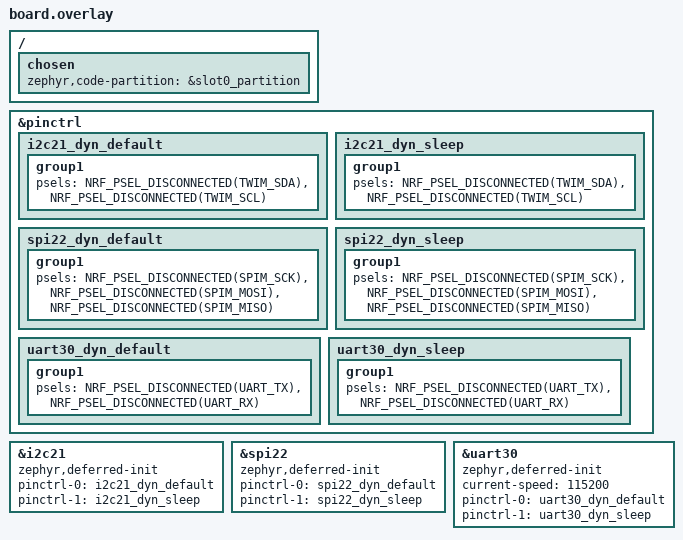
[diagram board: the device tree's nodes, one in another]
// nRF54L15 DK doesn't have USB, so no app.overlay for CDC ACM.

// Enable every free serial peripheral instance so CircuitPython can mux it to
// arbitrary pins at runtime. Each instance is enabled in one mode because the
// i2c/spi/uart nodes of an instance are the same peripheral (enforced by
// zephyr/soc/nordic/validate_enabled_instances.c). All signals are
// disconnected and the devices are marked zephyr,deferred-init so nothing is
// claimed at boot; iobroker initializes and routes a device when a busio
// object is constructed and de-initializes it on release.
//
// Instance 20 is left alone: uart20 is the console (main UART) and i2c20/spi20
// share that same peripheral, so they must not be enabled. Instance 00 is
// owned by spi00 and the MX25R64 SPI flash (no TWI00 on this SoC).

&pinctrl {
	i2c21_dyn_default: i2c21_dyn_default {
		group1 {
			psels = <NRF_PSEL_DISCONNECTED(TWIM_SDA)>,
				<NRF_PSEL_DISCONNECTED(TWIM_SCL)>;
		};
	};

	i2c21_dyn_sleep: i2c21_dyn_sleep {
		group1 {
			psels = <NRF_PSEL_DISCONNECTED(TWIM_SDA)>,
				<NRF_PSEL_DISCONNECTED(TWIM_SCL)>;
		};
	};

	spi22_dyn_default: spi22_dyn_default {
		group1 {
			psels = <NRF_PSEL_DISCONNECTED(SPIM_SCK)>,
				<NRF_PSEL_DISCONNECTED(SPIM_MOSI)>,
				<NRF_PSEL_DISCONNECTED(SPIM_MISO)>;
		};
	};

	spi22_dyn_sleep: spi22_dyn_sleep {
		group1 {
			psels = <NRF_PSEL_DISCONNECTED(SPIM_SCK)>,
				<NRF_PSEL_DISCONNECTED(SPIM_MOSI)>,
				<NRF_PSEL_DISCONNECTED(SPIM_MISO)>;
		};
	};

	uart30_dyn_default: uart30_dyn_default {
		group1 {
			psels = <NRF_PSEL_DISCONNECTED(UART_TX)>,
				<NRF_PSEL_DISCONNECTED(UART_RX)>;
		};
	};

	uart30_dyn_sleep: uart30_dyn_sleep {
		group1 {
			psels = <NRF_PSEL_DISCONNECTED(UART_TX)>,
				<NRF_PSEL_DISCONNECTED(UART_RX)>;
		};
	};
};

&i2c21 {
	status = "okay";
	zephyr,deferred-init;
	pinctrl-0 = <&i2c21_dyn_default>;
	pinctrl-1 = <&i2c21_dyn_sleep>;
	pinctrl-names = "default", "sleep";
};

&spi22 {
	status = "okay";
	zephyr,deferred-init;
	pinctrl-0 = <&spi22_dyn_default>;
	pinctrl-1 = <&spi22_dyn_sleep>;
	pinctrl-names = "default", "sleep";
};

&uart30 {
	status = "okay";
	zephyr,deferred-init;
	current-speed = <115200>;
	pinctrl-0 = <&uart30_dyn_default>;
	pinctrl-1 = <&uart30_dyn_sleep>;
	pinctrl-names = "default", "sleep";
};

/ {
	chosen {
		zephyr,code-partition = &slot0_partition;
	};
};
